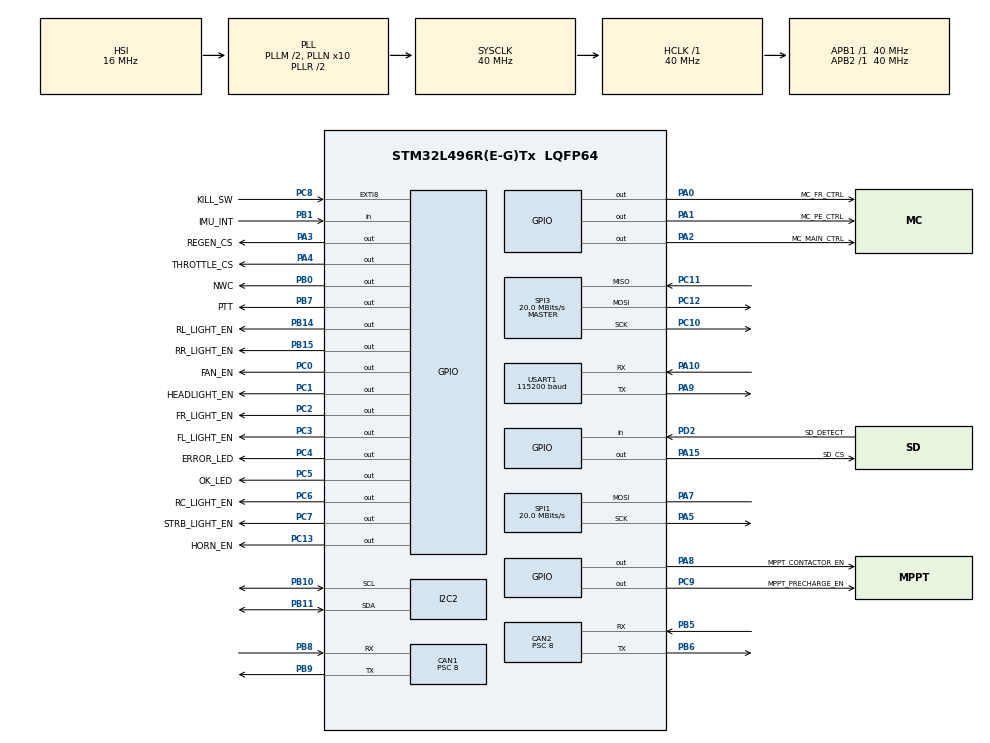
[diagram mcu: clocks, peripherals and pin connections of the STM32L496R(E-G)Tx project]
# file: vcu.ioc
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CAN1.BS1=CAN_BS1_8TQ
CAN1.BS2=CAN_BS2_1TQ
CAN1.CalculateBaudRate=500000
CAN1.CalculateTimeBit=2000
CAN1.CalculateTimeQuantum=200.0
CAN1.Prescaler=8
CAN2.BS1=CAN_BS1_8TQ
CAN2.BS2=CAN_BS2_1TQ
CAN2.CalculateBaudRate=500000
CAN2.CalculateTimeBit=2000
CAN2.CalculateTimeQuantum=200.0
CAN2.Prescaler=8
FREERTOS.Tasks01=defaultTask,24,128,StartDefaultTask,Default,NULL,Dynamic,NULL,NULL
FREERTOS.configTIMER_TASK_PRIORITY=32
I2C2.Timing=0x00909BEB
Mcu.Family=STM32L4
Mcu.Name=STM32L496R(E-G)Tx
Mcu.Package=LQFP64
NVIC.CAN1_RX0_IRQn=true\:5\:0\:false\:false\:true\:true\:true\:true\:true
NVIC.CAN1_RX1_IRQn=true\:5\:0\:false\:false\:true\:true\:true\:true\:true
NVIC.CAN2_RX0_IRQn=true\:5\:0\:false\:false\:true\:true\:true\:true\:true
NVIC.CAN2_RX1_IRQn=true\:5\:0\:false\:false\:true\:true\:true\:true\:true
NVIC.EXTI9_5_IRQn=true\:5\:0\:false\:false\:true\:true\:true\:true\:true
NVIC.PriorityGroup=NVIC_PRIORITYGROUP_4
NVIC.TIM1_TRG_COM_TIM17_IRQn=true\:15\:0\:false\:false\:true\:false\:false\:true\:true
NVIC.TimeBase=TIM1_TRG_COM_TIM17_IRQn
NVIC.TimeBaseIP=TIM17
PA0.GPIO_Label=MC_FR_CTRL
PA0.Signal=GPIO_Output
PA1.GPIO_Label=MC_PE_CTRL
PA1.Signal=GPIO_Output
PA10.Mode=Asynchronous
PA10.Signal=USART1_RX
PA13\ (JTMS/SWDIO).Mode=Trace_Asynchronous_SW
PA13\ (JTMS/SWDIO).Signal=SYS_JTMS-SWDIO
PA14\ (JTCK/SWCLK).Mode=Trace_Asynchronous_SW
PA14\ (JTCK/SWCLK).Signal=SYS_JTCK-SWCLK
PA15\ (JTDI).GPIO_Label=SD_CS
PA15\ (JTDI).Signal=GPIO_Output
PA2.GPIO_Label=MC_MAIN_CTRL
PA2.Signal=GPIO_Output
PA3.GPIO_Label=REGEN_CS
PA3.Signal=GPIO_Output
PA4.GPIO_Label=THROTTLE_CS
PA4.Signal=GPIO_Output
PA5.Mode=Simplex_Bidirectional_Master
PA5.Signal=SPI1_SCK
PA7.Mode=Simplex_Bidirectional_Master
PA7.Signal=SPI1_MOSI
PA8.GPIO_Label=MPPT_CONTACTOR_EN
PA8.Signal=GPIO_Output
PA9.Mode=Asynchronous
PA9.Signal=USART1_TX
PB0.GPIO_Label=NWC
PB0.Signal=GPIO_Output
PB1.GPIO_Label=IMU_INT
PB1.Signal=GPIO_Input
PB10.Mode=I2C
PB10.Signal=I2C2_SCL
PB11.Mode=I2C
PB11.Signal=I2C2_SDA
PB14.GPIO_Label=RL_LIGHT_EN
PB14.Signal=GPIO_Output
PB15.GPIO_Label=RR_LIGHT_EN
PB15.Signal=GPIO_Output
PB3\ (JTDO/TRACESWO).Mode=Trace_Asynchronous_SW
PB3\ (JTDO/TRACESWO).Signal=SYS_JTDO-SWO
PB5.Mode=CAN_Activate
PB5.Signal=CAN2_RX
PB6.Mode=CAN_Activate
PB6.Signal=CAN2_TX
PB7.GPIO_Label=PTT
PB7.Signal=GPIO_Output
PB8.Mode=CAN_Activate
PB8.Signal=CAN1_RX
PB9.Mode=CAN_Activate
PB9.Signal=CAN1_TX
PC0.GPIO_Label=FAN_EN
PC0.Signal=GPIO_Output
PC1.GPIO_Label=HEADLIGHT_EN
PC1.Signal=GPIO_Output
PC10.Mode=Full_Duplex_Master
PC10.Signal=SPI3_SCK
PC11.Mode=Full_Duplex_Master
PC11.Signal=SPI3_MISO
PC12.Mode=Full_Duplex_Master
PC12.Signal=SPI3_MOSI
PC13.GPIO_Label=HORN_EN
PC13.Signal=GPIO_Output
PC14-OSC32_IN\ (PC14).Mode=LSE-External-Oscillator
PC14-OSC32_IN\ (PC14).Signal=RCC_OSC32_IN
PC15-OSC32_OUT\ (PC15).Mode=LSE-External-Oscillator
PC15-OSC32_OUT\ (PC15).Signal=RCC_OSC32_OUT
PC2.GPIO_Label=FR_LIGHT_EN
PC2.Signal=GPIO_Output
PC3.GPIO_Label=FL_LIGHT_EN
PC3.Signal=GPIO_Output
PC4.GPIO_Label=ERROR_LED
PC4.Signal=GPIO_Output
PC5.GPIO_Label=OK_LED
PC5.Signal=GPIO_Output
PC6.GPIO_Label=RC_LIGHT_EN
PC6.Signal=GPIO_Output
PC7.GPIO_Label=STRB_LIGHT_EN
PC7.Signal=GPIO_Output
PC8.GPIO_Label=KILL_SW
PC8.Signal=GPXTI8
PC9.GPIO_Label=MPPT_PRECHARGE_EN
PC9.Signal=GPIO_Output
PD2.GPIO_Label=SD_DETECT
PD2.Signal=GPIO_Input
PH0-OSC_IN\ (PH0).Mode=HSE-External-Oscillator
PH0-OSC_IN\ (PH0).Signal=RCC_OSC_IN
PH1-OSC_OUT\ (PH1).Mode=HSE-External-Oscillator
PH1-OSC_OUT\ (PH1).Signal=RCC_OSC_OUT
ProjectManager.HeapSize=0x200
ProjectManager.StackSize=0x400
ProjectManager.TargetToolchain=Makefile
RCC.ADCFreq_Value=48000000
RCC.AHBFreq_Value=40000000
RCC.APB1Freq_Value=40000000
RCC.APB1TimFreq_Value=40000000
RCC.APB2Freq_Value=40000000
RCC.APB2TimFreq_Value=40000000
RCC.CortexFreq_Value=40000000
RCC.HCLKFreq_Value=40000000
RCC.HSE_VALUE=16000000
RCC.HSI48_VALUE=48000000
RCC.HSI_VALUE=16000000
RCC.MSI_VALUE=4000000
RCC.PLLM=2
RCC.PLLN=10
RCC.PLLSAI1N=12
RCC.PLLSourceVirtual=RCC_PLLSOURCE_HSI
RCC.SYSCLKFreq_VALUE=40000000
RCC.SYSCLKSource=RCC_SYSCLKSOURCE_PLLCLK
RCC.USBFreq_Value=48000000
RCC.VCOOutputFreq_Value=80000000
SPI1.CalculateBaudRate=20.0 MBits/s
SPI1.DataSize=SPI_DATASIZE_16BIT
SPI1.Direction=SPI_DIRECTION_1LINE
SPI1.Mode=SPI_MODE_MASTER
SPI1.VirtualType=VM_MASTER
SPI3.CalculateBaudRate=20.0 MBits/s
SPI3.DataSize=SPI_DATASIZE_8BIT
SPI3.Direction=SPI_DIRECTION_2LINES
SPI3.Mode=SPI_MODE_MASTER
SPI3.VirtualType=VM_MASTER
USART1.BaudRate=115200
USART1.VirtualMode-Asynchronous=VM_ASYNC
VP_FATFS_VS_Generic.Mode=User_defined
VP_FREERTOS_VS_CMSIS_V2.Mode=CMSIS_V2
VP_SYS_VS_tim17.Mode=TIM17
board=custom

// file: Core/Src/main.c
/* USER CODE BEGIN Header */
/**
  ******************************************************************************
  * @file           : main.c
  * @brief          : Main program body
  ******************************************************************************
  * @attention
  *
  * Copyright (c) 2023 STMicroelectronics.
  * All rights reserved.
  *
  * This software is licensed under terms that can be found in the LICENSE file
  * in the root directory of this software component.
  * If no LICENSE file comes with this software, it is provided AS-IS.
  *
  ******************************************************************************
  */
/* USER CODE END Header */
#include "main.h"
#include "cmsis_os.h"
#include "fatfs.h"

/* USER CODE BEGIN Includes */
#include "fatfs.h"
/* USER CODE END Includes */

/* USER CODE BEGIN PM */
extern uint16_t Timer1, Timer2;
/* USER CODE END PM */

CAN_HandleTypeDef hcan1;
CAN_HandleTypeDef hcan2;

I2C_HandleTypeDef hi2c2;

SPI_HandleTypeDef hspi1;
SPI_HandleTypeDef hspi3;

UART_HandleTypeDef huart1;

/* Definitions for defaultTask */
osThreadId_t defaultTaskHandle;
const osThreadAttr_t defaultTask_attributes = {
  .name = "defaultTask",
  .stack_size = 128 * 4,
  .priority = (osPriority_t) osPriorityNormal,
};
/* USER CODE BEGIN PV */
uint32_t utick = 0;
/* USER CODE END PV */

void SystemClock_Config(void);
static void MX_GPIO_Init(void);
static void MX_CAN1_Init(void);
static void MX_CAN2_Init(void);
static void MX_SPI1_Init(void);
static void MX_I2C2_Init(void);
static void MX_SPI3_Init(void);
static void MX_USART1_UART_Init(void);
void StartDefaultTask(void *argument);

/* USER CODE BEGIN PFP */
void CPP_UserSetup(void);
/* USER CODE END PFP */

int main(void)
{

  /* MCU Configuration--------------------------------------------------------*/

  /* Reset of all peripherals, Initializes the Flash interface and the Systick. */
  HAL_Init();

  /* Configure the system clock */
  SystemClock_Config();

  /* USER CODE BEGIN SysInit */

  // Set timebase interrupt to a high priority to enable HAL_Delay() during initialization
  HAL_NVIC_SetPriority(TIM1_TRG_COM_TIM17_IRQn, 1U, 0U);
  __enable_irq();
  __set_BASEPRI(6);

  /* USER CODE END SysInit */

  /* Initialize all configured peripherals */
  MX_GPIO_Init();
  MX_CAN1_Init();
  MX_CAN2_Init();
  MX_SPI1_Init();
  MX_I2C2_Init();
  MX_SPI3_Init();
  MX_USART1_UART_Init();
  MX_FATFS_Init();
  /* USER CODE BEGIN 2 */

  CPP_UserSetup();

  // Change timebase priority back to normal
  HAL_NVIC_SetPriority(TIM1_TRG_COM_TIM17_IRQn, 15U, 0U);

  /* USER CODE END 2 */

  /* Init scheduler */
  osKernelInitialize();

  /* Create the thread(s) */
  /* creation of defaultTask */
  defaultTaskHandle = osThreadNew(StartDefaultTask, NULL, &defaultTask_attributes);

  /* Start scheduler */
  osKernelStart();

  /* We should never get here as control is now taken by the scheduler */
  /* Infinite loop */
  while (1)
  {

  }
}

void SystemClock_Config(void)
{
  RCC_OscInitTypeDef RCC_OscInitStruct = {0};
  RCC_ClkInitTypeDef RCC_ClkInitStruct = {0};

  /** Configure the main internal regulator output voltage
  */
  if (HAL_PWREx_ControlVoltageScaling(PWR_REGULATOR_VOLTAGE_SCALE1) != HAL_OK)
  {
    Error_Handler();
  }

  /** Initializes the RCC Oscillators according to the specified parameters
  * in the RCC_OscInitTypeDef structure.
  */
  RCC_OscInitStruct.OscillatorType = RCC_OSCILLATORTYPE_HSI;
  RCC_OscInitStruct.HSIState = RCC_HSI_ON;
  RCC_OscInitStruct.HSICalibrationValue = RCC_HSICALIBRATION_DEFAULT;
  RCC_OscInitStruct.PLL.PLLState = RCC_PLL_ON;
  RCC_OscInitStruct.PLL.PLLSource = RCC_PLLSOURCE_HSI;
  RCC_OscInitStruct.PLL.PLLM = 2;
  RCC_OscInitStruct.PLL.PLLN = 10;
  RCC_OscInitStruct.PLL.PLLP = RCC_PLLP_DIV2;
  RCC_OscInitStruct.PLL.PLLQ = RCC_PLLQ_DIV2;
  RCC_OscInitStruct.PLL.PLLR = RCC_PLLR_DIV2;
  if (HAL_RCC_OscConfig(&RCC_OscInitStruct) != HAL_OK)
  {
    Error_Handler();
  }

  /** Initializes the CPU, AHB and APB buses clocks
  */
  RCC_ClkInitStruct.ClockType = RCC_CLOCKTYPE_HCLK|RCC_CLOCKTYPE_SYSCLK
                              |RCC_CLOCKTYPE_PCLK1|RCC_CLOCKTYPE_PCLK2;
  RCC_ClkInitStruct.SYSCLKSource = RCC_SYSCLKSOURCE_PLLCLK;
  RCC_ClkInitStruct.AHBCLKDivider = RCC_SYSCLK_DIV1;
  RCC_ClkInitStruct.APB1CLKDivider = RCC_HCLK_DIV1;
  RCC_ClkInitStruct.APB2CLKDivider = RCC_HCLK_DIV1;

  if (HAL_RCC_ClockConfig(&RCC_ClkInitStruct, FLASH_LATENCY_2) != HAL_OK)
  {
    Error_Handler();
  }
}

static void MX_CAN1_Init(void)
{

  hcan1.Instance = CAN1;
  hcan1.Init.Prescaler = 8;
  hcan1.Init.Mode = CAN_MODE_NORMAL;
  hcan1.Init.SyncJumpWidth = CAN_SJW_1TQ;
  hcan1.Init.TimeSeg1 = CAN_BS1_8TQ;
  hcan1.Init.TimeSeg2 = CAN_BS2_1TQ;
  hcan1.Init.TimeTriggeredMode = DISABLE;
  hcan1.Init.AutoBusOff = DISABLE;
  hcan1.Init.AutoWakeUp = DISABLE;
  hcan1.Init.AutoRetransmission = DISABLE;
  hcan1.Init.ReceiveFifoLocked = DISABLE;
  hcan1.Init.TransmitFifoPriority = DISABLE;
  if (HAL_CAN_Init(&hcan1) != HAL_OK)
  {
    Error_Handler();
  }

}

static void MX_CAN2_Init(void)
{

  hcan2.Instance = CAN2;
  hcan2.Init.Prescaler = 8;
  hcan2.Init.Mode = CAN_MODE_NORMAL;
  hcan2.Init.SyncJumpWidth = CAN_SJW_1TQ;
  hcan2.Init.TimeSeg1 = CAN_BS1_8TQ;
  hcan2.Init.TimeSeg2 = CAN_BS2_1TQ;
  hcan2.Init.TimeTriggeredMode = DISABLE;
  hcan2.Init.AutoBusOff = DISABLE;
  hcan2.Init.AutoWakeUp = DISABLE;
  hcan2.Init.AutoRetransmission = DISABLE;
  hcan2.Init.ReceiveFifoLocked = DISABLE;
  hcan2.Init.TransmitFifoPriority = DISABLE;
  if (HAL_CAN_Init(&hcan2) != HAL_OK)
  {
    Error_Handler();
  }

}

static void MX_I2C2_Init(void)
{

  hi2c2.Instance = I2C2;
  hi2c2.Init.Timing = 0x00909BEB;
  hi2c2.Init.OwnAddress1 = 0;
  hi2c2.Init.AddressingMode = I2C_ADDRESSINGMODE_7BIT;
  hi2c2.Init.DualAddressMode = I2C_DUALADDRESS_DISABLE;
  hi2c2.Init.OwnAddress2 = 0;
  hi2c2.Init.OwnAddress2Masks = I2C_OA2_NOMASK;
  hi2c2.Init.GeneralCallMode = I2C_GENERALCALL_DISABLE;
  hi2c2.Init.NoStretchMode = I2C_NOSTRETCH_DISABLE;
  if (HAL_I2C_Init(&hi2c2) != HAL_OK)
  {
    Error_Handler();
  }

  /** Configure Analogue filter
  */
  if (HAL_I2CEx_ConfigAnalogFilter(&hi2c2, I2C_ANALOGFILTER_ENABLE) != HAL_OK)
  {
    Error_Handler();
  }

  /** Configure Digital filter
  */
  if (HAL_I2CEx_ConfigDigitalFilter(&hi2c2, 0) != HAL_OK)
  {
    Error_Handler();
  }

}

static void MX_SPI1_Init(void)
{

  /* SPI1 parameter configuration*/
  hspi1.Instance = SPI1;
  hspi1.Init.Mode = SPI_MODE_MASTER;
  hspi1.Init.Direction = SPI_DIRECTION_1LINE;
  hspi1.Init.DataSize = SPI_DATASIZE_16BIT;
  hspi1.Init.CLKPolarity = SPI_POLARITY_LOW;
  hspi1.Init.CLKPhase = SPI_PHASE_1EDGE;
  hspi1.Init.NSS = SPI_NSS_SOFT;
  hspi1.Init.BaudRatePrescaler = SPI_BAUDRATEPRESCALER_2;
  hspi1.Init.FirstBit = SPI_FIRSTBIT_MSB;
  hspi1.Init.TIMode = SPI_TIMODE_DISABLE;
  hspi1.Init.CRCCalculation = SPI_CRCCALCULATION_DISABLE;
  hspi1.Init.CRCPolynomial = 7;
  hspi1.Init.CRCLength = SPI_CRC_LENGTH_DATASIZE;
  hspi1.Init.NSSPMode = SPI_NSS_PULSE_ENABLE;
  if (HAL_SPI_Init(&hspi1) != HAL_OK)
  {
    Error_Handler();
  }

}

static void MX_SPI3_Init(void)
{

  /* SPI3 parameter configuration*/
  hspi3.Instance = SPI3;
  hspi3.Init.Mode = SPI_MODE_MASTER;
  hspi3.Init.Direction = SPI_DIRECTION_2LINES;
  hspi3.Init.DataSize = SPI_DATASIZE_8BIT;
  hspi3.Init.CLKPolarity = SPI_POLARITY_LOW;
  hspi3.Init.CLKPhase = SPI_PHASE_1EDGE;
  hspi3.Init.NSS = SPI_NSS_SOFT;
  hspi3.Init.BaudRatePrescaler = SPI_BAUDRATEPRESCALER_2;
  hspi3.Init.FirstBit = SPI_FIRSTBIT_MSB;
  hspi3.Init.TIMode = SPI_TIMODE_DISABLE;
  hspi3.Init.CRCCalculation = SPI_CRCCALCULATION_DISABLE;
  hspi3.Init.CRCPolynomial = 7;
  hspi3.Init.CRCLength = SPI_CRC_LENGTH_DATASIZE;
  hspi3.Init.NSSPMode = SPI_NSS_PULSE_ENABLE;
  if (HAL_SPI_Init(&hspi3) != HAL_OK)
  {
    Error_Handler();
  }

}

static void MX_USART1_UART_Init(void)
{

  huart1.Instance = USART1;
  huart1.Init.BaudRate = 115200;
  huart1.Init.WordLength = UART_WORDLENGTH_8B;
  huart1.Init.StopBits = UART_STOPBITS_1;
  huart1.Init.Parity = UART_PARITY_NONE;
  huart1.Init.Mode = UART_MODE_TX_RX;
  huart1.Init.HwFlowCtl = UART_HWCONTROL_NONE;
  huart1.Init.OverSampling = UART_OVERSAMPLING_16;
  huart1.Init.OneBitSampling = UART_ONE_BIT_SAMPLE_DISABLE;
  huart1.AdvancedInit.AdvFeatureInit = UART_ADVFEATURE_NO_INIT;
  if (HAL_UART_Init(&huart1) != HAL_OK)
  {
    Error_Handler();
  }

}

static void MX_GPIO_Init(void)
{
  GPIO_InitTypeDef GPIO_InitStruct = {0};

  /* GPIO Ports Clock Enable */
  __HAL_RCC_GPIOC_CLK_ENABLE();
  __HAL_RCC_GPIOH_CLK_ENABLE();
  __HAL_RCC_GPIOA_CLK_ENABLE();
  __HAL_RCC_GPIOB_CLK_ENABLE();
  __HAL_RCC_GPIOD_CLK_ENABLE();

  /*Configure GPIO pin Output Level */
  HAL_GPIO_WritePin(GPIOC, HORN_EN_Pin|FAN_EN_Pin|HEADLIGHT_EN_Pin|FR_LIGHT_EN_Pin
                          |FL_LIGHT_EN_Pin|ERROR_LED_Pin|OK_LED_Pin|RC_LIGHT_EN_Pin
                          |STRB_LIGHT_EN_Pin|MPPT_PRECHARGE_EN_Pin, GPIO_PIN_RESET);

  /*Configure GPIO pin Output Level */
  HAL_GPIO_WritePin(GPIOA, MC_FR_CTRL_Pin|MC_PE_CTRL_Pin|MC_MAIN_CTRL_Pin|REGEN_CS_Pin
                          |THROTTLE_CS_Pin|MPPT_CONTACTOR_EN_Pin|SD_CS_Pin, GPIO_PIN_RESET);

  /*Configure GPIO pin Output Level */
  HAL_GPIO_WritePin(GPIOB, NWC_Pin|RL_LIGHT_EN_Pin|RR_LIGHT_EN_Pin|PTT_Pin, GPIO_PIN_RESET);

  /*Configure GPIO pins : HORN_EN_Pin FAN_EN_Pin HEADLIGHT_EN_Pin FR_LIGHT_EN_Pin
                           FL_LIGHT_EN_Pin ERROR_LED_Pin OK_LED_Pin RC_LIGHT_EN_Pin
                           STRB_LIGHT_EN_Pin MPPT_PRECHARGE_EN_Pin */
  GPIO_InitStruct.Pin = HORN_EN_Pin|FAN_EN_Pin|HEADLIGHT_EN_Pin|FR_LIGHT_EN_Pin
                          |FL_LIGHT_EN_Pin|ERROR_LED_Pin|OK_LED_Pin|RC_LIGHT_EN_Pin
                          |STRB_LIGHT_EN_Pin|MPPT_PRECHARGE_EN_Pin;
  GPIO_InitStruct.Mode = GPIO_MODE_OUTPUT_PP;
  GPIO_InitStruct.Pull = GPIO_NOPULL;
  GPIO_InitStruct.Speed = GPIO_SPEED_FREQ_LOW;
  HAL_GPIO_Init(GPIOC, &GPIO_InitStruct);

  /*Configure GPIO pins : MC_FR_CTRL_Pin MC_PE_CTRL_Pin MC_MAIN_CTRL_Pin REGEN_CS_Pin
                           THROTTLE_CS_Pin MPPT_CONTACTOR_EN_Pin SD_CS_Pin */
  GPIO_InitStruct.Pin = MC_FR_CTRL_Pin|MC_PE_CTRL_Pin|MC_MAIN_CTRL_Pin|REGEN_CS_Pin
                          |THROTTLE_CS_Pin|MPPT_CONTACTOR_EN_Pin|SD_CS_Pin;
  GPIO_InitStruct.Mode = GPIO_MODE_OUTPUT_PP;
  GPIO_InitStruct.Pull = GPIO_NOPULL;
  GPIO_InitStruct.Speed = GPIO_SPEED_FREQ_LOW;
  HAL_GPIO_Init(GPIOA, &GPIO_InitStruct);

  /*Configure GPIO pins : NWC_Pin RL_LIGHT_EN_Pin RR_LIGHT_EN_Pin PTT_Pin */
  GPIO_InitStruct.Pin = NWC_Pin|RL_LIGHT_EN_Pin|RR_LIGHT_EN_Pin|PTT_Pin;
  GPIO_InitStruct.Mode = GPIO_MODE_OUTPUT_PP;
  GPIO_InitStruct.Pull = GPIO_NOPULL;
  GPIO_InitStruct.Speed = GPIO_SPEED_FREQ_LOW;
  HAL_GPIO_Init(GPIOB, &GPIO_InitStruct);

  /*Configure GPIO pin : IMU_INT_Pin */
  GPIO_InitStruct.Pin = IMU_INT_Pin;
  GPIO_InitStruct.Mode = GPIO_MODE_INPUT;
  GPIO_InitStruct.Pull = GPIO_NOPULL;
  HAL_GPIO_Init(IMU_INT_GPIO_Port, &GPIO_InitStruct);

  /*Configure GPIO pin : KILL_SW_Pin */
  GPIO_InitStruct.Pin = KILL_SW_Pin;
  GPIO_InitStruct.Mode = GPIO_MODE_IT_RISING_FALLING;
  GPIO_InitStruct.Pull = GPIO_NOPULL;
  HAL_GPIO_Init(KILL_SW_GPIO_Port, &GPIO_InitStruct);

  /*Configure GPIO pin : SD_DETECT_Pin */
  GPIO_InitStruct.Pin = SD_DETECT_Pin;
  GPIO_InitStruct.Mode = GPIO_MODE_INPUT;
  GPIO_InitStruct.Pull = GPIO_NOPULL;
  HAL_GPIO_Init(SD_DETECT_GPIO_Port, &GPIO_InitStruct);

  /* EXTI interrupt init*/
  HAL_NVIC_SetPriority(EXTI9_5_IRQn, 5, 0);
  HAL_NVIC_EnableIRQ(EXTI9_5_IRQn);

}

void StartDefaultTask(void *argument)
{
  for(;;)
  {
    osDelay(1);
  }
}

void HAL_TIM_PeriodElapsedCallback(TIM_HandleTypeDef *htim)
{
  if (htim->Instance == TIM17) {
    HAL_IncTick();
  }
}

void Error_Handler(void)
{
  /* USER CODE BEGIN Error_Handler_Debug */
  /* User can add his own implementation to report the HAL error return state */
  __disable_irq();
  HAL_GPIO_WritePin(GPIOC, ERROR_LED_Pin, GPIO_PIN_SET);
  while (1)
  {
  }
  /* USER CODE END Error_Handler_Debug */
}
